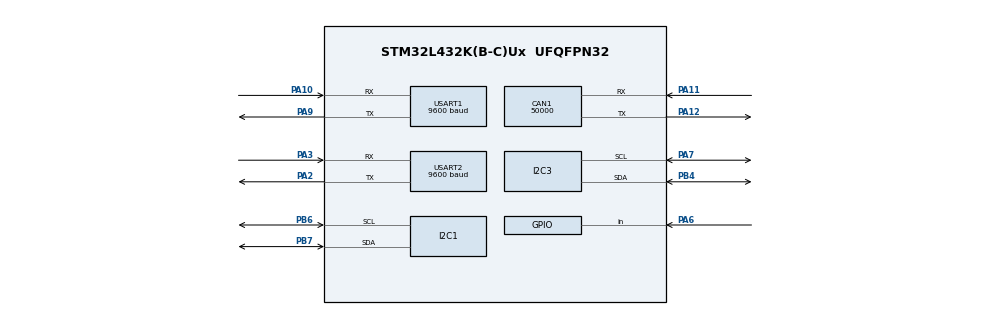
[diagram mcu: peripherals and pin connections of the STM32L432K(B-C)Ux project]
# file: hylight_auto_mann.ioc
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CAN1.BS1=CAN_BS1_2TQ
CAN1.BS2=CAN_BS2_2TQ
CAN1.CalculateBaudRate=50000
CAN1.CalculateTimeBit=20000
CAN1.CalculateTimeQuantum=4000.0
Dma.Request0=USART2_RX
Dma.Request1=USART1_RX
Dma.USART1_RX.1.Direction=DMA_PERIPH_TO_MEMORY
Dma.USART1_RX.1.Instance=DMA1_Channel5
Dma.USART1_RX.1.MemDataAlignment=DMA_MDATAALIGN_BYTE
Dma.USART1_RX.1.MemInc=DMA_MINC_ENABLE
Dma.USART1_RX.1.Mode=DMA_NORMAL
Dma.USART1_RX.1.PeriphDataAlignment=DMA_PDATAALIGN_BYTE
Dma.USART1_RX.1.PeriphInc=DMA_PINC_DISABLE
Dma.USART1_RX.1.Priority=DMA_PRIORITY_LOW
Dma.USART2_RX.0.Direction=DMA_PERIPH_TO_MEMORY
Dma.USART2_RX.0.Instance=DMA1_Channel6
Dma.USART2_RX.0.MemDataAlignment=DMA_MDATAALIGN_BYTE
Dma.USART2_RX.0.MemInc=DMA_MINC_ENABLE
Dma.USART2_RX.0.Mode=DMA_NORMAL
Dma.USART2_RX.0.PeriphDataAlignment=DMA_PDATAALIGN_BYTE
Dma.USART2_RX.0.PeriphInc=DMA_PINC_DISABLE
Dma.USART2_RX.0.Priority=DMA_PRIORITY_LOW
FREERTOS.Tasks01=CAN_Transmit,-1,128,can_logger_cycle,As weak,NULL,Dynamic,NULL,NULL;UART_Reception,-1,128,uart_notifications_cycle,As external,NULL,Dynamic,NULL,NULL;UART_Transmit,-1,128,uart_logger_cycle,As external,NULL,Dynamic,NULL,NULL;MUX_PRES,-1,128,mux_pres_cycle,As external,NULL,Dynamic,NULL,NULL
FREERTOS.configTOTAL_HEAP_SIZE=3000
FREERTOS.configUSE_NEWLIB_REENTRANT=1
I2C1.Timing=0x00100D14
I2C3.Timing=0x00100D14
Mcu.Family=STM32L4
Mcu.Name=STM32L432K(B-C)Ux
Mcu.Package=UFQFPN32
NVIC.DMA1_Channel5_IRQn=true\:5\:0\:false\:false\:true\:true\:false\:true\:true
NVIC.DMA1_Channel6_IRQn=true\:5\:0\:true\:false\:true\:true\:false\:true\:true
NVIC.PriorityGroup=NVIC_PRIORITYGROUP_4
NVIC.USART1_IRQn=true\:5\:0\:false\:false\:true\:true\:true\:true\:true
NVIC.USART2_IRQn=true\:5\:0\:false\:false\:true\:true\:true\:true\:true
PA10.Mode=Asynchronous
PA10.Signal=USART1_RX
PA11.Mode=CAN_Activate
PA11.Signal=CAN1_RX
PA12.Mode=CAN_Activate
PA12.Signal=CAN1_TX
PA2.Mode=Asynchronous
PA2.Signal=USART2_TX
PA3.Mode=Asynchronous
PA3.Signal=USART2_RX
PA6.Signal=GPIO_Input
PA7.Mode=I2C
PA7.Signal=I2C3_SCL
PA9.Mode=Asynchronous
PA9.Signal=USART1_TX
PB4\ (NJTRST).Mode=I2C
PB4\ (NJTRST).Signal=I2C3_SDA
PB6.Mode=I2C
PB6.Signal=I2C1_SCL
PB7.Mode=I2C
PB7.Signal=I2C1_SDA
ProjectManager.HeapSize=0x200
ProjectManager.StackSize=0x400
ProjectManager.TargetToolchain=STM32CubeIDE
RCC.HSE_VALUE=8000000
RCC.HSI48_VALUE=48000000
RCC.HSI_VALUE=16000000
RCC.LSE_VALUE=32768
RCC.MSI_VALUE=4000000
RCC.VCOOutputFreq_Value=32000000
USART1.BaudRate=9600
USART1.VirtualMode-Asynchronous=VM_ASYNC
USART2.BaudRate=9600
USART2.VirtualMode-Asynchronous=VM_ASYNC
VP_FREERTOS_VS_CMSIS_V1.Mode=CMSIS_V1
board=custom

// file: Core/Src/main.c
/* USER CODE BEGIN Header */
/**
  ******************************************************************************
  * @file           : main.c
  * @brief          : Main program body
  ******************************************************************************
  * @attention
  *
  * Copyright (c) 2025 STMicroelectronics.
  * All rights reserved.
  *
  * This software is licensed under terms that can be found in the LICENSE file
  * in the root directory of this software component.
  * If no LICENSE file comes with this software, it is provided AS-IS.
  *
  ******************************************************************************
  */
/* USER CODE END Header */
#include "main.h"
#include "cmsis_os.h"

/* USER CODE BEGIN Includes */
#include "thread_proto.h"
/* USER CODE END Includes */

CAN_HandleTypeDef hcan1;

I2C_HandleTypeDef hi2c1;
I2C_HandleTypeDef hi2c3;

UART_HandleTypeDef huart1;
UART_HandleTypeDef huart2;
DMA_HandleTypeDef hdma_usart1_rx;
DMA_HandleTypeDef hdma_usart2_rx;

osThreadId CAN_TransmitHandle;
osThreadId UART_ReceptionHandle;
osThreadId UART_TransmitHandle;
osThreadId MUX_PRESHandle;

void SystemClock_Config(void);
static void MX_GPIO_Init(void);
static void MX_DMA_Init(void);
static void MX_CAN1_Init(void);
static void MX_USART1_UART_Init(void);
static void MX_USART2_UART_Init(void);
static void MX_I2C1_Init(void);
static void MX_I2C3_Init(void);
void can_logger_cycle(void const * argument);
extern void uart_notifications_cycle(void const * argument);
extern void uart_logger_cycle(void const * argument);
extern void mux_pres_cycle(void const * argument);

int main(void)
{

  /* MCU Configuration--------------------------------------------------------*/

  /* Reset of all peripherals, Initializes the Flash interface and the Systick. */
  HAL_Init();

  /* Configure the system clock */
  SystemClock_Config();

  /* Initialize all configured peripherals */
  MX_GPIO_Init();
  MX_DMA_Init();
  MX_CAN1_Init();
  MX_USART1_UART_Init();
  MX_USART2_UART_Init();
  MX_I2C1_Init();
  MX_I2C3_Init();
  /* USER CODE BEGIN 2 */
  can_gpio_verification = (HAL_GPIO_ReadPin(GPIOA, GPIO_PIN_6)==GPIO_PIN_SET);
  perform_setup_threads(&huart1,&huart2,&hi2c1,&hi2c3,&hdma_usart1_rx,USART1,&hcan1);

  /* USER CODE END 2 */

  /* Create the thread(s) */
  /* definition and creation of CAN_Transmit */
  osThreadDef(CAN_Transmit, can_logger_cycle, osPriorityBelowNormal, 0, 128);
  CAN_TransmitHandle = osThreadCreate(osThread(CAN_Transmit), NULL);

  /* definition and creation of UART_Reception */
  osThreadDef(UART_Reception, uart_notifications_cycle, osPriorityBelowNormal, 0, 128);
  UART_ReceptionHandle = osThreadCreate(osThread(UART_Reception), NULL);

  /* definition and creation of UART_Transmit */
  osThreadDef(UART_Transmit, uart_logger_cycle, osPriorityBelowNormal, 0, 128);
  UART_TransmitHandle = osThreadCreate(osThread(UART_Transmit), NULL);

  /* definition and creation of MUX_PRES */
  osThreadDef(MUX_PRES, mux_pres_cycle, osPriorityBelowNormal, 0, 128);
  MUX_PRESHandle = osThreadCreate(osThread(MUX_PRES), NULL);

  /* Start scheduler */
  osKernelStart();

  /* We should never get here as control is now taken by the scheduler */

  /* Infinite loop */
  while (1)
  {

  }
}

void SystemClock_Config(void)
{
  RCC_OscInitTypeDef RCC_OscInitStruct = {0};
  RCC_ClkInitTypeDef RCC_ClkInitStruct = {0};

  /** Configure the main internal regulator output voltage
  */
  if (HAL_PWREx_ControlVoltageScaling(PWR_REGULATOR_VOLTAGE_SCALE1) != HAL_OK)
  {
    Error_Handler();
  }

  /** Initializes the RCC Oscillators according to the specified parameters
  * in the RCC_OscInitTypeDef structure.
  */
  RCC_OscInitStruct.OscillatorType = RCC_OSCILLATORTYPE_MSI;
  RCC_OscInitStruct.MSIState = RCC_MSI_ON;
  RCC_OscInitStruct.MSICalibrationValue = 0;
  RCC_OscInitStruct.MSIClockRange = RCC_MSIRANGE_6;
  RCC_OscInitStruct.PLL.PLLState = RCC_PLL_NONE;
  if (HAL_RCC_OscConfig(&RCC_OscInitStruct) != HAL_OK)
  {
    Error_Handler();
  }

  /** Initializes the CPU, AHB and APB buses clocks
  */
  RCC_ClkInitStruct.ClockType = RCC_CLOCKTYPE_HCLK|RCC_CLOCKTYPE_SYSCLK
                              |RCC_CLOCKTYPE_PCLK1|RCC_CLOCKTYPE_PCLK2;
  RCC_ClkInitStruct.SYSCLKSource = RCC_SYSCLKSOURCE_MSI;
  RCC_ClkInitStruct.AHBCLKDivider = RCC_SYSCLK_DIV1;
  RCC_ClkInitStruct.APB1CLKDivider = RCC_HCLK_DIV1;
  RCC_ClkInitStruct.APB2CLKDivider = RCC_HCLK_DIV1;

  if (HAL_RCC_ClockConfig(&RCC_ClkInitStruct, FLASH_LATENCY_0) != HAL_OK)
  {
    Error_Handler();
  }
}

static void MX_CAN1_Init(void)
{

  hcan1.Instance = CAN1;
  hcan1.Init.Prescaler = 16;
  hcan1.Init.Mode = CAN_MODE_NORMAL;
  hcan1.Init.SyncJumpWidth = CAN_SJW_1TQ;
  hcan1.Init.TimeSeg1 = CAN_BS1_2TQ;
  hcan1.Init.TimeSeg2 = CAN_BS2_2TQ;
  hcan1.Init.TimeTriggeredMode = DISABLE;
  hcan1.Init.AutoBusOff = DISABLE;
  hcan1.Init.AutoWakeUp = DISABLE;
  hcan1.Init.AutoRetransmission = DISABLE;
  hcan1.Init.ReceiveFifoLocked = DISABLE;
  hcan1.Init.TransmitFifoPriority = DISABLE;
  if (HAL_CAN_Init(&hcan1) != HAL_OK)
  {
    Error_Handler();
  }

}

static void MX_I2C1_Init(void)
{

  hi2c1.Instance = I2C1;
  hi2c1.Init.Timing = 0x00100D14;
  hi2c1.Init.OwnAddress1 = 0;
  hi2c1.Init.AddressingMode = I2C_ADDRESSINGMODE_7BIT;
  hi2c1.Init.DualAddressMode = I2C_DUALADDRESS_DISABLE;
  hi2c1.Init.OwnAddress2 = 0;
  hi2c1.Init.OwnAddress2Masks = I2C_OA2_NOMASK;
  hi2c1.Init.GeneralCallMode = I2C_GENERALCALL_DISABLE;
  hi2c1.Init.NoStretchMode = I2C_NOSTRETCH_DISABLE;
  if (HAL_I2C_Init(&hi2c1) != HAL_OK)
  {
    Error_Handler();
  }

  /** Configure Analogue filter
  */
  if (HAL_I2CEx_ConfigAnalogFilter(&hi2c1, I2C_ANALOGFILTER_ENABLE) != HAL_OK)
  {
    Error_Handler();
  }

  /** Configure Digital filter
  */
  if (HAL_I2CEx_ConfigDigitalFilter(&hi2c1, 0) != HAL_OK)
  {
    Error_Handler();
  }

}

static void MX_I2C3_Init(void)
{

  hi2c3.Instance = I2C3;
  hi2c3.Init.Timing = 0x00100D14;
  hi2c3.Init.OwnAddress1 = 0;
  hi2c3.Init.AddressingMode = I2C_ADDRESSINGMODE_7BIT;
  hi2c3.Init.DualAddressMode = I2C_DUALADDRESS_DISABLE;
  hi2c3.Init.OwnAddress2 = 0;
  hi2c3.Init.OwnAddress2Masks = I2C_OA2_NOMASK;
  hi2c3.Init.GeneralCallMode = I2C_GENERALCALL_DISABLE;
  hi2c3.Init.NoStretchMode = I2C_NOSTRETCH_DISABLE;
  if (HAL_I2C_Init(&hi2c3) != HAL_OK)
  {
    Error_Handler();
  }

  /** Configure Analogue filter
  */
  if (HAL_I2CEx_ConfigAnalogFilter(&hi2c3, I2C_ANALOGFILTER_ENABLE) != HAL_OK)
  {
    Error_Handler();
  }

  /** Configure Digital filter
  */
  if (HAL_I2CEx_ConfigDigitalFilter(&hi2c3, 0) != HAL_OK)
  {
    Error_Handler();
  }

}

static void MX_USART1_UART_Init(void)
{

  huart1.Instance = USART1;
  huart1.Init.BaudRate = 9600;
  huart1.Init.WordLength = UART_WORDLENGTH_8B;
  huart1.Init.StopBits = UART_STOPBITS_1;
  huart1.Init.Parity = UART_PARITY_NONE;
  huart1.Init.Mode = UART_MODE_TX_RX;
  huart1.Init.HwFlowCtl = UART_HWCONTROL_NONE;
  huart1.Init.OverSampling = UART_OVERSAMPLING_16;
  huart1.Init.OneBitSampling = UART_ONE_BIT_SAMPLE_DISABLE;
  huart1.AdvancedInit.AdvFeatureInit = UART_ADVFEATURE_NO_INIT;
  if (HAL_UART_Init(&huart1) != HAL_OK)
  {
    Error_Handler();
  }

}

static void MX_USART2_UART_Init(void)
{

  huart2.Instance = USART2;
  huart2.Init.BaudRate = 9600;
  huart2.Init.WordLength = UART_WORDLENGTH_8B;
  huart2.Init.StopBits = UART_STOPBITS_1;
  huart2.Init.Parity = UART_PARITY_NONE;
  huart2.Init.Mode = UART_MODE_TX_RX;
  huart2.Init.HwFlowCtl = UART_HWCONTROL_NONE;
  huart2.Init.OverSampling = UART_OVERSAMPLING_16;
  huart2.Init.OneBitSampling = UART_ONE_BIT_SAMPLE_DISABLE;
  huart2.AdvancedInit.AdvFeatureInit = UART_ADVFEATURE_NO_INIT;
  if (HAL_UART_Init(&huart2) != HAL_OK)
  {
    Error_Handler();
  }

}

static void MX_DMA_Init(void)
{

  /* DMA controller clock enable */
  __HAL_RCC_DMA1_CLK_ENABLE();

  /* DMA interrupt init */
  /* DMA1_Channel5_IRQn interrupt configuration */
  HAL_NVIC_SetPriority(DMA1_Channel5_IRQn, 5, 0);
  HAL_NVIC_EnableIRQ(DMA1_Channel5_IRQn);
  /* DMA1_Channel6_IRQn interrupt configuration */
  HAL_NVIC_SetPriority(DMA1_Channel6_IRQn, 5, 0);
  HAL_NVIC_EnableIRQ(DMA1_Channel6_IRQn);

}

static void MX_GPIO_Init(void)
{
  GPIO_InitTypeDef GPIO_InitStruct = {0};

  /* GPIO Ports Clock Enable */
  __HAL_RCC_GPIOA_CLK_ENABLE();
  __HAL_RCC_GPIOB_CLK_ENABLE();

  /*Configure GPIO pin : PA6 */
  GPIO_InitStruct.Pin = GPIO_PIN_6;
  GPIO_InitStruct.Mode = GPIO_MODE_INPUT;
  GPIO_InitStruct.Pull = GPIO_NOPULL;
  HAL_GPIO_Init(GPIOA, &GPIO_InitStruct);

}

__weak void can_logger_cycle(void const * argument)
{
  for(;;)
  {
	  osDelay(1);
  }
}

void Error_Handler(void)
{
  __disable_irq();
  while (1)
  {
  }
}
